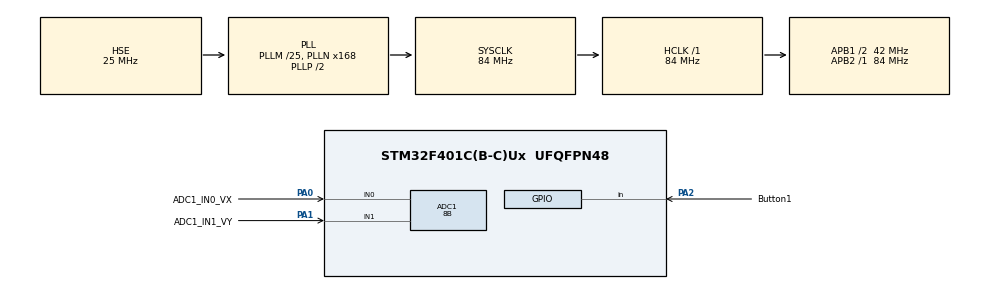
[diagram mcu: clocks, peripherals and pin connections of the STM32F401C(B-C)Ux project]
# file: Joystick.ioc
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Mcu.Family=STM32F4
RCC.PLLSourceVirtual=RCC_PLLSOURCE_HSE
PA2.GPIO_PuPd=GPIO_PULLUP
Dma.ADC1.0.Instance=DMA2_Stream0
RCC.CortexFreq_Value=84000000
ADC1.Rank-0\#ChannelRegularConversion=1
ADC1.ContinuousConvMode=ENABLE
PH1\ -\ OSC_OUT.Mode=HSE-External-Oscillator
RCC.APB1CLKDivider=RCC_HCLK_DIV2
RCC.SYSCLKSource=RCC_SYSCLKSOURCE_PLLCLK
ProjectManager.StackSize=0x400
PA0-WKUP.GPIO_Label=ADC1_IN0_VX
PA0-WKUP.Signal=ADCx_IN0
PA13.Signal=SYS_JTMS-SWDIO
Dma.ADC1.0.PeriphDataAlignment=DMA_PDATAALIGN_WORD
PH0\ -\ OSC_IN.Mode=HSE-External-Oscillator
PH0\ -\ OSC_IN.Signal=RCC_OSC_IN
ProjectManager.TargetToolchain=STM32CubeIDE
Dma.ADC1.0.Mode=DMA_CIRCULAR
RCC.HCLKFreq_Value=84000000
ADC1.Resolution=ADC_RESOLUTION_8B
Dma.ADC1.0.Priority=DMA_PRIORITY_LOW
RCC.APB2TimFreq_Value=84000000
ADC1.Channel-1\#ChannelRegularConversion=ADC_CHANNEL_1
Dma.ADC1.0.Direction=DMA_PERIPH_TO_MEMORY
NVIC.DMA2_Stream0_IRQn=true\:0\:0\:false\:false\:true\:false\:true
RCC.LSE_VALUE=32768
Dma.ADC1.0.MemDataAlignment=DMA_MDATAALIGN_WORD
PA1.Signal=ADCx_IN1
RCC.AHBFreq_Value=84000000
ADC1.Channel-0\#ChannelRegularConversion=ADC_CHANNEL_0
RCC.HSE_VALUE=25000000
PH1\ -\ OSC_OUT.Signal=RCC_OSC_OUT
ADC1.ScanConvMode=ENABLE
board=custom
RCC.VCOOutputFreq_Value=168000000
RCC.APB2Freq_Value=84000000
PA14.Mode=Serial_Wire
Dma.ADC1.0.PeriphInc=DMA_PINC_DISABLE
PA1.GPIO_Label=ADC1_IN1_VY
SH.ADCx_IN0.0=ADC1_IN0,IN0
ADC1.DMAContinuousRequests=ENABLE
ADC1.NbrOfConversion=2
PA13.Mode=Serial_Wire
Mcu.Name=STM32F401C(B-C)Ux
ADC1.SamplingTime-0\#ChannelRegularConversion=ADC_SAMPLETIME_144CYCLES
PA2.Signal=GPIO_Input
RCC.48MHZClocksFreq_Value=42000000
ADC1.SamplingTime-1\#ChannelRegularConversion=ADC_SAMPLETIME_144CYCLES
RCC.SYSCLKFreq_VALUE=84000000
Mcu.Package=UFQFPN48
ADC1.master=1
ADC1.Rank-1\#ChannelRegularConversion=2
PA2.GPIO_Label=Button1
PA14.Signal=SYS_JTCK-SWCLK
Dma.ADC1.0.MemInc=DMA_MINC_ENABLE
ProjectManager.HeapSize=0x200
RCC.HSI_VALUE=16000000
NVIC.PriorityGroup=NVIC_PRIORITYGROUP_4
ADC1.NbrOfConversionFlag=1
SH.ADCx_IN1.0=ADC1_IN1,IN1
RCC.PLLM=25
RCC.PLLN=168
RCC.APB1TimFreq_Value=84000000
Dma.ADC1.0.FIFOMode=DMA_FIFOMODE_DISABLE
Dma.Request0=ADC1
RCC.APB1Freq_Value=42000000

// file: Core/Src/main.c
/* USER CODE BEGIN Header */
/**
  ******************************************************************************
  * @file           : main.c
  * @brief          : Main program body
  ******************************************************************************
  * @attention
  *
  * <h2><center>&copy; Copyright (c) 2023 STMicroelectronics.
  * All rights reserved.</center></h2>
  *
  * This software component is licensed by ST under BSD 3-Clause license,
  * the "License"; You may not use this file except in compliance with the
  * License. You may obtain a copy of the License at:
  *                        opensource.org/licenses/BSD-3-Clause
  *
  ******************************************************************************
  */
/* USER CODE END Header */
#include "main.h"
#include "adc.h"
#include "dma.h"
#include "gpio.h"

/* USER CODE BEGIN PM */

	/* ADC */

		int ADC_Read[2] = {0};
		int Button1 = 0;
		int Joystick_x = 0;
		int Joystick_y = 0;
		int Omega = 0;
		int State_button = 0;
		int Switch = 0;
		long last_time = 0, current_time = 0;;

/* USER CODE END PM */

void SystemClock_Config(void);
/* USER CODE BEGIN PFP */

	/* MAP JOYSTICK */

		double map(double x, double in_min, double in_max, double out_min, double out_max) {
		  return (x - in_min) * (out_max - out_min) / (in_max - in_min) + out_min;
		}

	/* MAP JOYSTICK */

		void Joystick() {
			  if (ADC_Read[0] >= 0 && ADC_Read[0] <= 120){
				  Joystick_x = map(ADC_Read[0], 0, 120, 0, 128);
			  }
			  if (ADC_Read[0] >= 130 && ADC_Read[0] <= 255){
				  Joystick_x = map(ADC_Read[0], 130, 255, 128, 255);
			  }
			  if (ADC_Read[0] > 120 && ADC_Read[0] < 130){
				  Joystick_x = 128;
			  }

			  if (ADC_Read[1] >= 0 && ADC_Read[1] <= 120){
				  Joystick_y = map(ADC_Read[1], 0, 120, 0, 128);
			  }
			  if (ADC_Read[1] >= 130 && ADC_Read[1] <= 255){
				  Joystick_y = map(ADC_Read[1], 130, 255, 128, 255);
			  }
			  if (ADC_Read[1] > 120 && ADC_Read[1] < 130){
				  Joystick_y = 128;
			  }

			  if (Switch == 0){
				  Joystick_y = Joystick_y;
				  Omega = 128;
			  }
			  else {
				  Omega = Joystick_y;
				  Joystick_y = 128;
			  }
		}

/* USER CODE END PFP */

int main(void)
{

  /* MCU Configuration--------------------------------------------------------*/

  /* Reset of all peripherals, Initializes the Flash interface and the Systick. */
  HAL_Init();

  /* Configure the system clock */
  SystemClock_Config();

  /* Initialize all configured peripherals */
  MX_GPIO_Init();
  MX_DMA_Init();
  MX_ADC1_Init();
  /* USER CODE BEGIN 2 */

  HAL_ADC_Start_DMA(&hadc1, &ADC_Read, 2);
//  HAL_Delay(50);

  /* USER CODE END 2 */

  /* Infinite loop */
  while (1)
  {

    /* USER CODE BEGIN 3 */

		  Button1 = HAL_GPIO_ReadPin(Button1_GPIO_Port, Button1_Pin);

		  if (Button1 == 0 && State_button == 0){
			  State_button = 1;
			  last_time = HAL_GetTick();
		  }
		  if (Button1 == 1 && State_button == 1){
			  State_button = 0;
			  current_time = HAL_GetTick();
		  }
		  if (current_time - last_time > 100){
			  last_time = current_time;
			  Switch = !Switch;
		  }
		  Joystick();

  }
  /* USER CODE END 3 */
}

void SystemClock_Config(void)
{
  RCC_OscInitTypeDef RCC_OscInitStruct = {0};
  RCC_ClkInitTypeDef RCC_ClkInitStruct = {0};

  /** Configure the main internal regulator output voltage
  */
  __HAL_RCC_PWR_CLK_ENABLE();
  __HAL_PWR_VOLTAGESCALING_CONFIG(PWR_REGULATOR_VOLTAGE_SCALE2);
  /** Initializes the RCC Oscillators according to the specified parameters
  * in the RCC_OscInitTypeDef structure.
  */
  RCC_OscInitStruct.OscillatorType = RCC_OSCILLATORTYPE_HSE;
  RCC_OscInitStruct.HSEState = RCC_HSE_ON;
  RCC_OscInitStruct.PLL.PLLState = RCC_PLL_ON;
  RCC_OscInitStruct.PLL.PLLSource = RCC_PLLSOURCE_HSE;
  RCC_OscInitStruct.PLL.PLLM = 25;
  RCC_OscInitStruct.PLL.PLLN = 168;
  RCC_OscInitStruct.PLL.PLLP = RCC_PLLP_DIV2;
  RCC_OscInitStruct.PLL.PLLQ = 4;
  if (HAL_RCC_OscConfig(&RCC_OscInitStruct) != HAL_OK)
  {
    Error_Handler();
  }
  /** Initializes the CPU, AHB and APB buses clocks
  */
  RCC_ClkInitStruct.ClockType = RCC_CLOCKTYPE_HCLK|RCC_CLOCKTYPE_SYSCLK
                              |RCC_CLOCKTYPE_PCLK1|RCC_CLOCKTYPE_PCLK2;
  RCC_ClkInitStruct.SYSCLKSource = RCC_SYSCLKSOURCE_PLLCLK;
  RCC_ClkInitStruct.AHBCLKDivider = RCC_SYSCLK_DIV1;
  RCC_ClkInitStruct.APB1CLKDivider = RCC_HCLK_DIV2;
  RCC_ClkInitStruct.APB2CLKDivider = RCC_HCLK_DIV1;

  if (HAL_RCC_ClockConfig(&RCC_ClkInitStruct, FLASH_LATENCY_2) != HAL_OK)
  {
    Error_Handler();
  }
}

void Error_Handler(void)
{
  __disable_irq();
  while (1)
  {
  }
}

/************************ (C) COPYRIGHT STMicroelectronics *****END OF FILE****/
